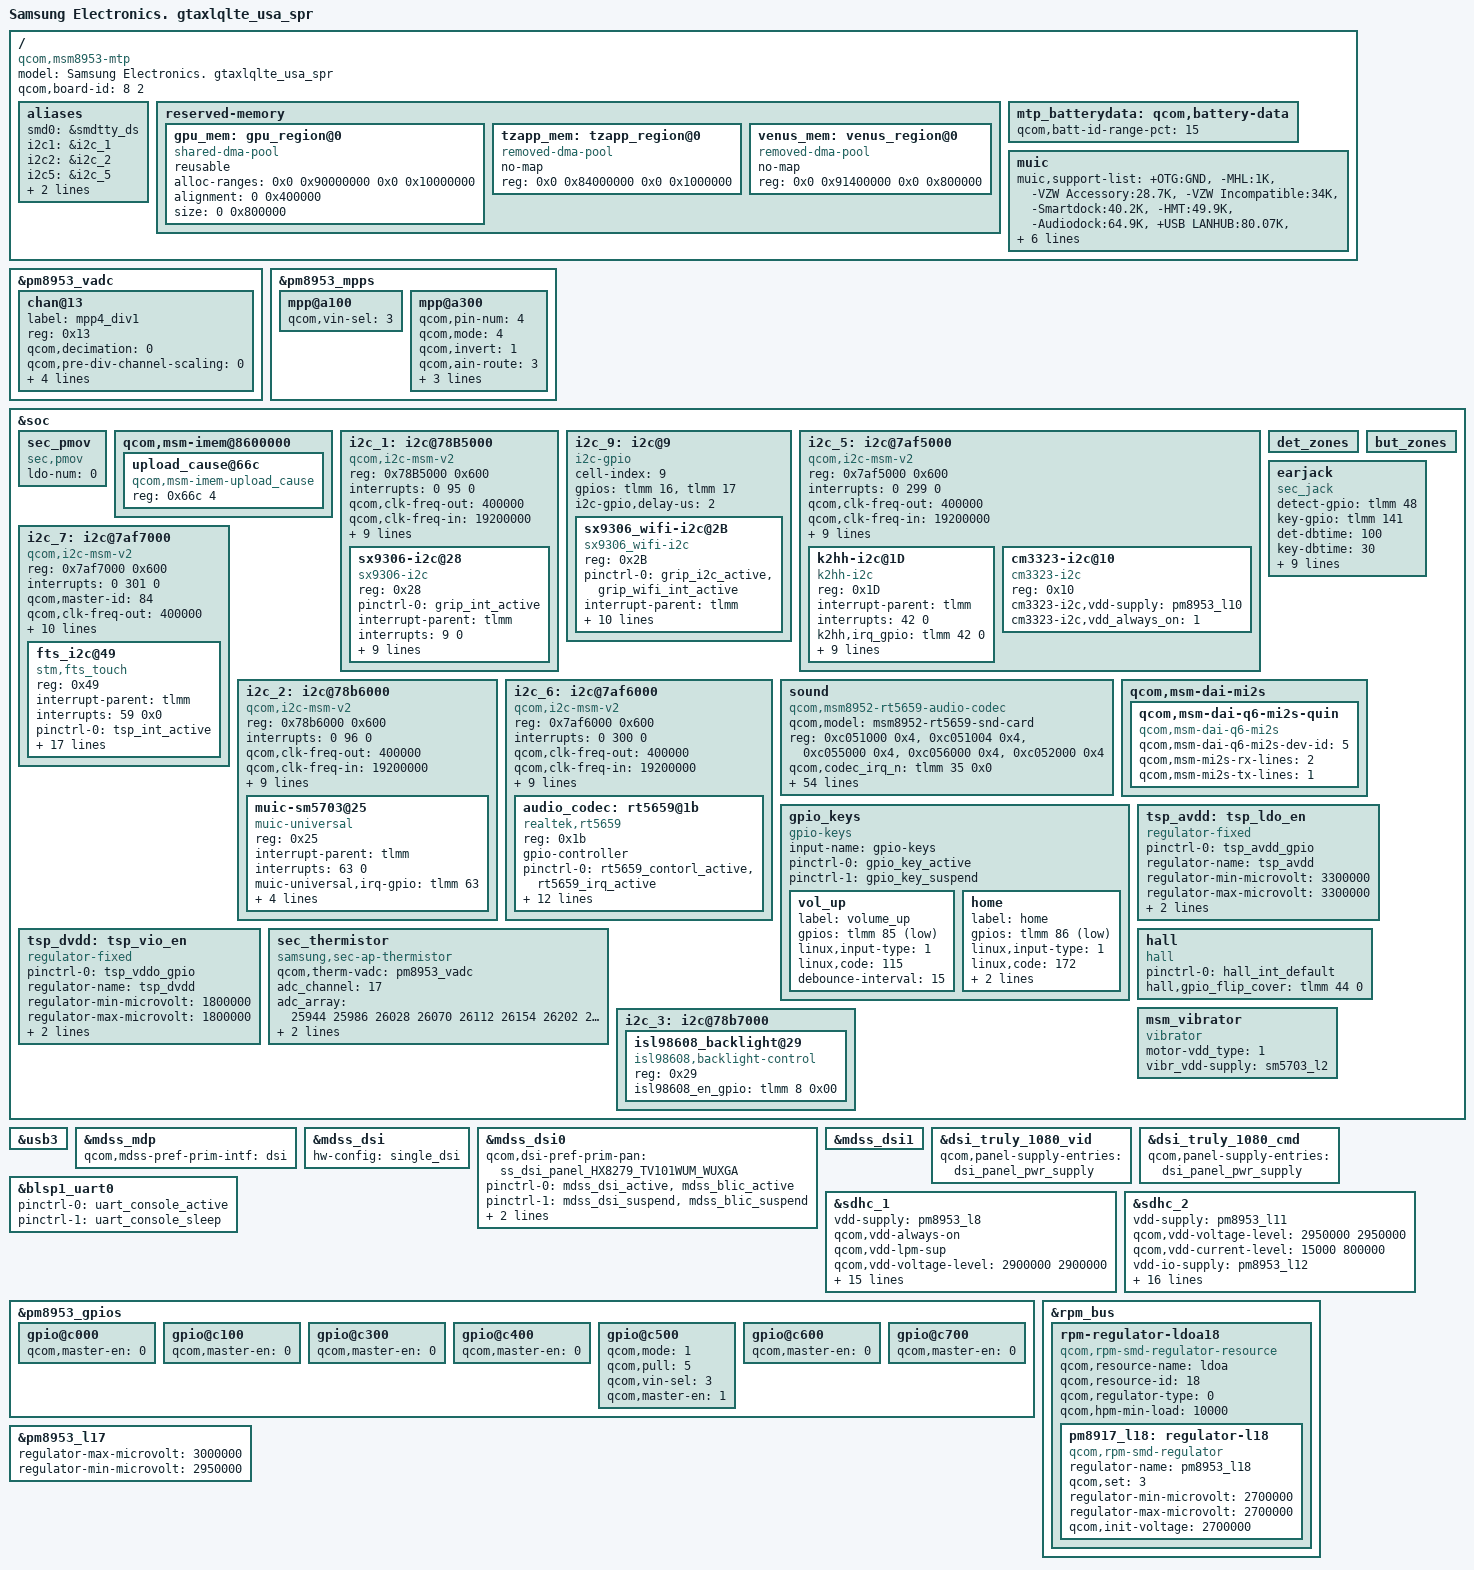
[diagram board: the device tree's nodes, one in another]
/*
 * Copyright (c) 2015, The Linux Foundation. All rights reserved.
 *
 * This program is free software; you can redistribute it and/or modify
 * it under the terms of the GNU General Public License version 2 and
 * only version 2 as published by the Free Software Foundation.
 *
 * This program is distributed in the hope that it will be useful,
 * but WITHOUT ANY WARRANTY; without even the implied warranty of
 * MERCHANTABILITY or FITNESS FOR A PARTICULAR PURPOSE.  See the
 * GNU General Public License for more details.
 */

/dts-v1/;

#include "../../qcom/msm8953.dtsi"
#include "msm-sec-audio.dtsi"
#include "msm8953-sec-common.dtsi"
#include "msm8953-sec-gtaxlqlte_usa_spr-pinctrl-r00.dtsi"
#include "msm8953-sec-gtaxlqlte_usa_spr-battery-r02.dtsi"
#include "msm8953-gtaxlqlte_usa_spr-sm5703.dtsi"
#include "msm8953-camera-sensor-gtaxlq-spr-r00.dtsi"

/ {
	model = "Samsung Electronics. gtaxlqlte_usa_spr";
	compatible = "qcom,msm8953-mtp", "qcom,msm8953", "qcom,mtp";
	qcom,board-id= <8 2>;
	aliases {
		/delete-property/ spi3;

		smd0 = &smdtty_ds;
		i2c1 = &i2c_1;
		i2c2 = &i2c_2;
		i2c5 = &i2c_5;
		i2c6 = &i2c_6;
		i2c7 = &i2c_7;
	};

	reserved-memory {
		/delete-node/ gpu_region@0;
		gpu_mem: gpu_region@0 {
			compatible = "shared-dma-pool";
			reusable;
			alloc-ranges = <0x0 0x90000000 0x0 0x10000000>;
			alignment = <0 0x400000>;
			size = <0 0x800000>;
		};

		/delete-node/ tzapp_region@0;
		tzapp_mem: tzapp_region@0 {
			compatible = "removed-dma-pool";
			no-map;
			reg = <0x0 0x84000000 0x0 0x1000000>;
		};

		/delete-node/ venus_region@0;
		venus_mem: venus_region@0 {
			compatible = "removed-dma-pool";
			no-map;
			reg = <0x0 0x91400000 0x0 0x800000>;
		};
	};
};

&pm8953_vadc {
	chan@13 {
		label = "mpp4_div1";
		reg = <0x13>;
		qcom,decimation = <0>;
		qcom,pre-div-channel-scaling = <0>;
		qcom,calibration-type = "absolute";
		qcom,scale-function = <0>;
		qcom,hw-settle-time = <5>;
		qcom,fast-avg-setup = <0>;
	};
};

&pm8953_mpps {
	mpp@a100 {
		qcom,vin-sel = <3>;
		status = "okay";
	};

	mpp@a300 {
		qcom,pin-num = <4>;
		qcom,mode = <4>; /* AIN input */
		qcom,invert = <1>; /* Enable MPP */
		qcom,ain-route = <3>; /* AMUX 8 */
		qcom,master-en = <1>;
		qcom,src-sel = <0>; /* Function constant */
		qcom,vin-sel = <3>;
		status = "okay";
	};
};

&soc {
	sec_pmov {
		compatible = "sec,pmov";

		/* pinctrl-names = "default";
		pinctrl-0 = <&nc_gpio_default>; */

		ldo-num = <0>;
		/*ldo0-supply = <&pm8953_l17>;
		 ldo1-supply = <&pm8953_lx>; */
	};

	qcom,msm-imem@8600000 {
		upload_cause@66c { /* CONFIG_SEC_DEBUG */
			compatible = "qcom,msm-imem-upload_cause";
			reg = <0x66c 4>;
		};
	};

	i2c_1: i2c@78B5000 { /* BLSP1 QUP0 */
		compatible = "qcom,i2c-msm-v2";
		#address-cells = <1>;
		#size-cells = <0>;
		reg-names = "qup_phys_addr";
		reg = <0x78B5000 0x600>;
		interrupt-names = "qup_irq";
		interrupts = <0 95 0>;
		qcom,clk-freq-out = <400000>;
		qcom,clk-freq-in  = <19200000>;
		clock-names = "iface_clk", "core_clk";
		clocks = <&clock_gcc clk_gcc_blsp1_ahb_clk>,
			<&clock_gcc clk_gcc_blsp1_qup1_i2c_apps_clk>;

		pinctrl-names = "i2c_active", "i2c_sleep";
		pinctrl-0 = <&i2c_1_active>;
		pinctrl-1 = <&i2c_1_sleep>;
		qcom,noise-rjct-scl = <0>;
		qcom,noise-rjct-sda = <0>;
		qcom,master-id = <86>;
		dmas = <&dma_blsp1 4 64 0x20000020 0x20>,
			<&dma_blsp1 5 32 0x20000020 0x20>;
		dma-names = "tx", "rx";

		sx9306-i2c@28{
			compatible = "sx9306-i2c";
			reg = <0x28>;
			pinctrl-names = "default";
			pinctrl-0 = <&grip_int_active>;
			interrupt-parent = <&tlmm>;
			interrupts = <9 0>;
			sx9306-i2c,nirq-gpio = <&tlmm 9 0x00>;
			sx9306-i2c,ctrl0 = <0x14>; /* Scanperiod : 60 */
			sx9306-i2c,ctrl2 = <0x57>; /* Gain: 4, Freq : 167, Resolution : Finest */
			sx9306-i2c,ctrl3 = <0x02>; /* Rawfilter: Medium */
			sx9306-i2c,ctrl5 = <0x0f>; /* AVGNEG:001 AVGPOS : 111 */ 
			sx9306-i2c,normal-thd = <5>; /* normal touch threshold */
			sx9306-i2c,ch-main = <2>; /* channel number */
			sx9306-i2c,ch-sub1 = <0xff>; /*oxff: Not be used sub channel */
			sx9306-i2c,ta-thd = <0x0f>; /* TA threhold : 300 */
		};
	};

	i2c_9: i2c@9 { /* SW I2C */
		cell-index = <9>;
		compatible = "i2c-gpio";
		gpios = <&tlmm 16 0 /* sda */
			&tlmm 17 0 /* scl */
		>;
		i2c-gpio,delay-us = <2>;
		#address-cells = <1>;
		#size-cells = <0>;

		sx9306_wifi-i2c@2B{
			compatible = "sx9306_wifi-i2c";
			reg = <0x2B>;
			pinctrl-names = "default";
			pinctrl-0 = <&grip_i2c_active &grip_wifi_int_active>;
			interrupt-parent = <&tlmm>;
			interrupts = <1 0>;
			sx9306_wifi-i2c,nirq-gpio = <&tlmm 1 0x00>;
			sx9306_wifi-i2c,ctrl0 = <0x04>; /* Scanperiod : 30 */
			sx9306_wifi-i2c,ctrl2 = <0x57>; /* Gain:4, Freq : 167, Resolution : Finest */
			sx9306_wifi-i2c,ctrl3 = <0x02>; /* Rawfilter: Medium */
			sx9306_wifi-i2c,ctrl5 = <0x0f>; /* AVGNEG:001 AVGPOS : 111 */
			sx9306_wifi-i2c,normal-thd = <5>; /* normal touch threshold */
			sx9306_wifi-i2c,ch-main = <2>; /* channel number */
			sx9306_wifi-i2c,ch-sub1 = <0xff>; /*oxff: Not be used sub channel */
			sx9306_wifi-i2c,ta-thd = <0x0f>; /* TA threhold : 300 */	
		};
	};

	i2c_5: i2c@7af5000 { /* BLSP2 QUP1 */
		compatible = "qcom,i2c-msm-v2";
		#address-cells = <1>;
		#size-cells = <0>;
		reg-names = "qup_phys_addr";
		reg = <0x7af5000 0x600>;
		interrupt-names = "qup_irq";
		interrupts = <0 299 0>;
		qcom,clk-freq-out = <400000>;
		qcom,clk-freq-in  = <19200000>;
		clock-names = "iface_clk", "core_clk";
		clocks = <&clock_gcc clk_gcc_blsp2_ahb_clk>,
			<&clock_gcc clk_gcc_blsp2_qup1_i2c_apps_clk>;

		pinctrl-names = "i2c_active", "i2c_sleep";
		pinctrl-0 = <&i2c_5_active>;
		pinctrl-1 = <&i2c_5_sleep>;
		qcom,noise-rjct-scl = <0>;
		qcom,noise-rjct-sda = <0>;
		qcom,master-id = <84>;
		dmas = <&dma_blsp2 4 64 0x20000020 0x20>,
			<&dma_blsp2 5 32 0x20000020 0x20>;
		dma-names = "tx", "rx";

		k2hh-i2c@1D {
			compatible = "k2hh-i2c";
			reg = <0x1D>;
			interrupt-parent = <&tlmm>;
			interrupts = <42 0>;
			k2hh,irq_gpio = <&tlmm 42 0>;
			k2hh,vio-supply = <&pm8953_l5>;
			k2hh,axis_map_x = <0>;
			k2hh,axis_map_y = <1>;
			k2hh,axis_map_z = <2>;
			k2hh,negate_x = <0>;
			k2hh,negate_y = <0>;
			k2hh,negate_z = <1>;
			k2hh,poll_interval = <100>;
			k2hh,min_interval = <2>;
		};

		cm3323-i2c@10 {
			compatible = "cm3323-i2c";
			reg = <0x10>;
			cm3323-i2c,vdd-supply = <&pm8953_l10>;
			cm3323-i2c,vdd_always_on = <1>;
		};
	};

	i2c_7: i2c@7af7000 { /* BLSP2 QUP3 */
		compatible = "qcom,i2c-msm-v2";
		#address-cells = <1>;
		#size-cells = <0>;
		reg-names = "qup_phys_addr";
		reg = <0x7af7000 0x600>;
		interrupt-names = "qup_irq";
		interrupts = <0 301 0>;
		qcom,master-id = <84>;
		qcom,clk-freq-out = <400000>;
		qcom,clk-freq-in  = <19200000>;
		clock-names = "iface_clk", "core_clk";
		clocks = <&clock_gcc clk_gcc_blsp2_ahb_clk>,
			<&clock_gcc clk_gcc_blsp2_qup3_i2c_apps_clk>;
		pinctrl-names = "i2c_active", "i2c_sleep";
		pinctrl-0 = <&i2c_7_active>;
		pinctrl-1 = <&i2c_7_suspend>;
		qcom,noise-rjct-scl = <0>;
		qcom,noise-rjct-sda = <0>;
		qcom,disable-dma;
		dmas = <&dma_blsp2 8 64 0x20000020 0x20>,
			<&dma_blsp2 9 32 0x20000020 0x20>;
		dma-names = "tx", "rx";
	};

	i2c_2: i2c@78b6000 { /* BLSP1 QUP2 */
		compatible = "qcom,i2c-msm-v2";
		#address-cells = <1>;
		#size-cells = <0>;
		reg-names = "qup_phys_addr";
		reg = <0x78b6000 0x600>;
		interrupt-names = "qup_irq";
		interrupts = <0 96 0>;
		qcom,clk-freq-out = <400000>;
		qcom,clk-freq-in  = <19200000>;
		clock-names = "iface_clk", "core_clk";
		clocks = <&clock_gcc clk_gcc_blsp1_ahb_clk>,
			<&clock_gcc clk_gcc_blsp1_qup2_i2c_apps_clk>;
		pinctrl-names = "i2c_active", "i2c_sleep";
		pinctrl-0 = <&i2c_2_active>;
		pinctrl-1 = <&i2c_2_sleep>;
		qcom,noise-rjct-scl = <0>;
		qcom,noise-rjct-sda = <0>;
		qcom,master-id = <86>;
		dmas = <&dma_blsp1 6 64 0x20000020 0x20>,
			<&dma_blsp1 7 32 0x20000020 0x20>;
		dma-names = "tx", "rx";
	};

	i2c_6: i2c@7af6000 { /* BLSP2 QUP2 */
		compatible = "qcom,i2c-msm-v2";
		#address-cells = <1>;
		#size-cells = <0>;
		reg-names = "qup_phys_addr";
		reg = <0x7af6000 0x600>;
		interrupt-names = "qup_irq";
		interrupts = <0 300 0>;
		qcom,clk-freq-out = <400000>;
		qcom,clk-freq-in  = <19200000>;
		clock-names = "iface_clk", "core_clk";
		clocks = <&clock_gcc clk_gcc_blsp2_ahb_clk>,
			<&clock_gcc clk_gcc_blsp2_qup2_i2c_apps_clk>;
		pinctrl-names = "i2c_active", "i2c_sleep";
		pinctrl-0 = <&i2c_6_active>;
		pinctrl-1 = <&i2c_6_sleep>;
		qcom,noise-rjct-scl = <0>;
		qcom,noise-rjct-sda = <0>;
		qcom,master-id = <84>;
		dmas = <&dma_blsp2 6 64 0x20000020 0x20>,
			<&dma_blsp2 7 32 0x20000020 0x20>;
		dma-names = "tx", "rx";

		audio_codec: rt5659@1b {
			compatible = "realtek,rt5659";
			reg = <0x1b>;
			gpio-controller;
			#gpio-cells = <2>;
			pinctrl-names = "default", "sleep";
			pinctrl-0 = <&rt5659_contorl_active &rt5659_irq_active>;
			pinctrl-1 = <&rt5659_contorl_suspend &rt5659_irq_suspend>;

			interrupts = <35 0>;
			interrupt-parent = <&tlmm>;

			realtek,in3-differential;
			realtek,in4-differential;
			realtek,noise-gate1-hp-enabled;

			realtek,gpio_reset = <&tlmm 71 0x0>;
			realtek,gpio_ldo = <&tlmm 74 0x00>;
			realtek,gpio_3p3_en = <&tlmm 73 0x00>;

			imp_table = <
				/* min      max     gain   bias */
				    0       10       10      5
				    11      21       5       5
				    22      85       0       5
				    86      839      0       1
				    840     1023     0       1
			>;
		};
	};

	det_zones: det_zones {
		#list-det-cells = <4>;
	};

	but_zones: but_zones {
		#list-but-cells = <3>;
	};

	earjack {
		compatible = "sec_jack";
		detect-gpio = <&tlmm 48 0x0>;
		key-gpio = <&tlmm 141 0x0>;
		det-dbtime = <100>;
		key-dbtime = <30>;

		det-zones-list = <&det_zones 0 10000 10 2>,
				 <&det_zones 750 10000 10 2>,
				 <&det_zones 751 10000 10 1>,
				 <&det_zones 9999 10000 10 1>;
		but-zones-list = <&but_zones 226 0 235>, /* KEY_MEDIA:226 */
				 <&but_zones 582 236 265>, /* KEY_VOICECOMMAND:582 */
				 <&but_zones 115 266 360>, /* KEY_VOLUMEUP:115 */
				 <&but_zones 114 361 999>; /* KEY_VOLUMEDOWN:114 */

		pinctrl-names = "earjack_gpio_active",
				"earjack_gpio_suspend";
		pinctrl-0 = <&earjack_det_act &earjack_switch_act>;
		pinctrl-1 = <&earjack_det_sus &earjack_switch_sus>;
	};

	sound {
		compatible = "qcom,msm8952-rt5659-audio-codec";
		qcom,model = "msm8952-rt5659-snd-card";
		reg = <0xc051000 0x4>,
		      <0xc051004 0x4>,
		      <0xc055000 0x4>,
		      <0xc056000 0x4>,
		      <0xc052000 0x4>;
		reg-names = "csr_gp_io_mux_mic_ctl",
			    "csr_gp_io_mux_spkr_ctl",
			    "csr_gp_io_lpaif_pri_pcm_pri_mode_muxsel",
			    "csr_gp_io_lpaif_sec_pcm_sec_mode_muxsel",
			    "csr_gp_io_mux_quin_ctl";

		qcom,codec_irq_n = <&tlmm 35 0x0>;

		qcom,mpp-standalone-mode;
		qcom,mpp-channel-scaling = <4 1 1>;
		qcom,earjack-read-vadc = <&pm8953_vadc>;
		qcom,msm-ext-pa = "quinary";
		qcom,msm-mclk-freq = <19200000>;
		qcom,codec_ear_bias = <0>;
		qcom,msm-hs-micbias-type = "External";
		qcom,audio-routing =
			"HP", "HPOL",
			"HP", "HPOR",
			"RCV", "MONOOUT",
			"SPK", "SPOL",
			"SPK", "SPOR",
			"IN1P", "Headset Mic",
			"IN1N", "Headset Mic",
			"IN3P", "MICBIAS3",
			"IN3P", "Sub Mic",
			"IN3N", "Sub Mic",
			"IN4P", "MICBIAS2",
			"IN4P", "Main Mic",
			"IN4N", "Main Mic";
		qcom,msm-gpios =
			"quat_i2s",
			"quin_i2s";
		qcom,pinctrl-names =
			"all_off",
			"quin_i2s_act",
			"quat_i2s_act",
			"quin_quat_i2s_act";
		pinctrl-names =
			"all_off",
			"quin_i2s_act",
			"quat_i2s_act",
			"quin_quat_i2s_act";
		pinctrl-0 = <&quin_tlmm_lines_sus &quin_tlmm_ws_lines_sus &gp_clk1_suspend>;
		pinctrl-1 = <&quin_tlmm_lines_act &quin_tlmm_ws_lines_act &gp_clk1_active>;
		pinctrl-2 = <&quin_tlmm_lines_act &quin_tlmm_ws_lines_act &gp_clk1_active>;
		pinctrl-3 = <&quin_tlmm_lines_act &quin_tlmm_ws_lines_act &gp_clk1_active>;
		asoc-platform = <&pcm0>, <&pcm1>, <&pcm2>, <&voip>, <&voice>,
				<&loopback>, <&compress>, <&hostless>,
				<&afe>, <&lsm>, <&routing>, <&lpa>;
		asoc-platform-names = "msm-pcm-dsp.0", "msm-pcm-dsp.1",
				"msm-pcm-dsp.2", "msm-voip-dsp",
				"msm-pcm-voice", "msm-pcm-loopback",
				"msm-compress-dsp", "msm-pcm-hostless",
				"msm-pcm-afe", "msm-lsm-client",
				"msm-pcm-routing", "msm-pcm-lpa";
		asoc-cpu = <&dai_pri_auxpcm>,
				<&dai_mi2s0>, <&dai_mi2s1>,
				<&dai_mi2s2>, <&dai_mi2s3>,
				<&dai_mi2s5>, <&dai_mi2s6>,
				<&bt_sco_rx>, <&bt_sco_tx>,
				<&int_fm_rx>, <&int_fm_tx>,
				<&afe_pcm_rx>, <&afe_pcm_tx>,
				<&afe_proxy_rx>, <&afe_proxy_tx>,
				<&incall_record_rx>, <&incall_record_tx>,
				<&incall_music_rx>, <&incall_music_2_rx>;
		asoc-cpu-names = "msm-dai-q6-auxpcm.1",
				"msm-dai-q6-mi2s.0", "msm-dai-q6-mi2s.1",
				"msm-dai-q6-mi2s.2", "msm-dai-q6-mi2s.3",
				"msm-dai-q6-mi2s.5", "msm-dai-q6-mi2s.6",
				"msm-dai-q6-dev.12288", "msm-dai-q6-dev.12289",
				"msm-dai-q6-dev.12292", "msm-dai-q6-dev.12293",
				"msm-dai-q6-dev.224", "msm-dai-q6-dev.225",
				"msm-dai-q6-dev.241", "msm-dai-q6-dev.240",
				"msm-dai-q6-dev.32771", "msm-dai-q6-dev.32772",
				"msm-dai-q6-dev.32773", "msm-dai-q6-dev.32770";
		asoc-codec = <&stub_codec>, <&audio_codec>;
		asoc-codec-names = "msm-stub-codec.1", "rt5659";

		clock-names = "ext-mclk";
		clocks = <&clock_gcc clk_gcc_camss_gp1_clk>;
		realtek,hp_impdeance_sensing_enable;
	};

	qcom,msm-dai-mi2s {
		qcom,msm-dai-q6-mi2s-quin {
			compatible = "qcom,msm-dai-q6-mi2s";
			qcom,msm-dai-q6-mi2s-dev-id = <5>;
			qcom,msm-mi2s-rx-lines = <2>;
			qcom,msm-mi2s-tx-lines = <1>;
		};
	};

	gpio_keys {
		compatible = "gpio-keys";
		input-name = "gpio-keys";
		pinctrl-names = "tlmm_gpio_key_active","tlmm_gpio_key_suspend";
		pinctrl-0 = <&gpio_key_active>;
		pinctrl-1 = <&gpio_key_suspend>;

		vol_up {
			label = "volume_up";
			gpios = <&tlmm 85 0x1>;
			linux,input-type = <1>;
			linux,code = <115>;
			debounce-interval = <15>;
		};

		home {
			label = "home";
			gpios = <&tlmm 86 0x1>;
			linux,input-type = <1>;
			linux,code = <172>;
			gpio-key,wakeup;
			debounce-interval = <15>;
		};
	};

	tsp_avdd:tsp_ldo_en {
		compatible = "regulator-fixed";
		pinctrl-names = "default";
		pinctrl-0 = <&tsp_avdd_gpio>;
		regulator-name = "tsp_avdd";
		regulator-min-microvolt = <3300000>;
		regulator-max-microvolt = <3300000>;
		gpio = <&tlmm 95 0>;
		enable-active-high;
	};

	tsp_dvdd:tsp_vio_en {
		compatible = "regulator-fixed";
		pinctrl-names = "default";
		pinctrl-0 = <&tsp_vddo_gpio>;
		regulator-name = "tsp_dvdd";
		regulator-min-microvolt = <1800000>;
		regulator-max-microvolt = <1800000>;
		gpio = <&tlmm 132 0>;
		enable-active-high;
	};

	sec_thermistor {
		compatible = "samsung,sec-ap-thermistor";
		qcom,therm-vadc = <&pm8953_vadc>;
		status = "okay";
		adc_channel = <17>;
		adc_array = <25944 25986 26028 26070 26112 26154 26202 26251
                                         26299 26347 26396 26455 26515 26575 26634 26694
                                         26760 26825 26891 26957 27023 27102 27181 27260
                                         27339 27418 27518 27617 27716 27815 27915 28021
                                         28128 28235 28341 28448 28570 28692 28814 28935
                                         29057 29202 29346 29490 29634 29778 29942 30106
                                         30269 30433 30596 30775 30954 31133 31312 31490
                                         31685 31880 32075 32270 32465 32676 32887 33098
                                         33309 33520 33730 33939 34148 34358 34567 34780
                                         34993 35206 35420 35633 35842 36052 36262 36471
                                         36681 36888 37096 37303 37510 37718 37805 37892
                                         38064 38236 38408 38593 38778 38962 39139 39316
                                         39468 39620 39772 39924 40075 40204 40332 40461
                                         40589 40717 40852 40987 41122 41257 41392>;

		temp_array = <900 890 880 870 860 850 840 830 820 810
			800 790 780 770 760 750 740 730 720 710
			700 690 680 670 660 650 640 630 620 610
			600 590 580 570 560 550 540 530 520 510
			500 490 480 470 460 450 440 430 420 410
			400 390 380 370 360 350 340 330 320 310
			300 290 280 270 260 250 240 230 220 210 
			200 190 180 170 160 150 140 130 120 110 
			100 90 80 70 60 50 40 30 20 10 
			0 (-10) (-20) (-30) (-40) (-50) (-60) (-70) (-80) (-90)
			(-100) (-110) (-120) (-130) (-140) (-150) (-160) (-170) (-180) (-190)
			(-200)>;
	};

	hall {
		compatible = "hall";
		status = "okay";
		pinctrl-names = "default";
		pinctrl-0 = <&hall_int_default>;
		hall,gpio_flip_cover = <&tlmm 44 0>;
	};

	msm_vibrator {
		compatible = "vibrator";
		motor-vdd_type = <1>; /* 0: gpio, 1: pmic */
		vibr_vdd-supply = <&sm5703_l2>;
	};
};

&usb3 {
	/delete-property/ vbus_dwc3-supply;
};

&i2c_7 {
	fts_i2c@49 {
		compatible = "stm,fts_touch";
		reg = <0x49>;
		interrupt-parent = <&tlmm>;
		interrupts = <59 0x0>;
		pinctrl-names = "tsp_gpio_active", "tsp_gpio_suspend";
		pinctrl-0 = <&tsp_int_active>;
		pinctrl-1 = <&tsp_int_suspend>;
		stm,irq_gpio = <&tlmm 59 0x0>;
		stm,irq_type = <8200>;
		stm,tsp_id1 = <&tlmm 67 0x0>;
		stm,tsp_id2 = <&tlmm 68 0x0>;
		stm,project_name = "GTAXLQLTE";
		stm,model_name = "T587P";
		stm,regulator_dvdd = "tsp_dvdd";
		stm,regulator_avdd = "tsp_avdd";
		stm,num_lines = <28 16>;		/* rx tx */
		stm,max_coords = <1199 1919>;	/* x y */
		stm,firmware_name = "tsp_stm/stm_gtaxlqlte.fw";
		stm,num_touchkey = <2>;
		stm,bringup = <0>;
		stm,support_lpm;
		clock-names = "iface_clk", "core_clk";
		clocks = <&clock_gcc clk_gcc_blsp2_ahb_clk>,
			<&clock_gcc clk_gcc_blsp2_qup3_i2c_apps_clk>;
	};
};		

&i2c_2 {
	muic-sm5703@25 {
		compatible = "muic-universal";
		reg = <0x25>;
		interrupt-parent = <&tlmm>;
		interrupts = <63 0>;
		muic-universal,irq-gpio = <&tlmm 63 0x00>;
		sm5705,wakeup;
		muic-universal,chip_name = "sm,sm5703";
		pinctrl-0 = <&sm5703_interrupt_default &sm5703_rst_default>;
	};

};


#include "../../qcom/msm8953-mdss-panels.dtsi"
#include "../../../../../../drivers/video/msm/mdss/samsung/HX8279_TV101WUM/dsi_panel_HX8279_TV101WUM_WUXGA_video.dtsi"
#include "../../../../../../drivers/video/msm/mdss/samsung/PBA_BOOTING_HD/dsi_panel_PBA_BOOTING_hd_video.dtsi"

&mdss_mdp {
	qcom,mdss-pref-prim-intf = "dsi";
};

&mdss_dsi {
	hw-config = "single_dsi";
};

&mdss_dsi0 {
	/delete-property/ lab-supply;
	/delete-property/ ibb-supply;
	qcom,dsi-pref-prim-pan = <&ss_dsi_panel_HX8279_TV101WUM_WUXGA>;
	pinctrl-names = "mdss_default", "mdss_sleep";
	pinctrl-0 = <&mdss_dsi_active &mdss_blic_active>;
	pinctrl-1 = <&mdss_dsi_suspend &mdss_blic_suspend>;

	qcom,platform-reset-gpio = <&tlmm 50 0>;
	qcom,platform-enable-gpio = <&tlmm 94 0>;
};

&mdss_dsi1 {
	/delete-property/ lab-supply;
	/delete-property/ ibb-supply;
};

&soc {
	i2c_3: i2c@78b7000 { /* BLSP1 QUP3 */
		status = "okay";

		isl98608_backlight@29 {
			compatible = "isl98608,backlight-control";
			reg = <0x29>;

			isl98608_en_gpio = <&tlmm 8 0x00>;
		};
	};
};
&dsi_truly_1080_vid {
	qcom,panel-supply-entries = <&dsi_panel_pwr_supply>;
};

&dsi_truly_1080_cmd {
	qcom,panel-supply-entries = <&dsi_panel_pwr_supply>;
};

&blsp1_uart0 {
	status = "ok";
	pinctrl-names = "default";
	pinctrl-0 = <&uart_console_active>;
	pinctrl-1 = <&uart_console_sleep>;
};

&sdhc_1 {
	/* device core power supply */
	vdd-supply = <&pm8953_l8>;
	qcom,vdd-always-on;
	qcom,vdd-lpm-sup;
	qcom,vdd-voltage-level = <2900000 2900000>;
	qcom,vdd-current-level = <200 570000>;

	/* device communication power supply */
	vdd-io-supply = <&pm8953_l5>;
	qcom,vdd-io-always-on;
	qcom,vdd-io-lpm-sup;
	qcom,vdd-io-voltage-level = <1800000 1800000>;
	qcom,vdd-io-current-level = <200 325000>;

	pinctrl-names = "active", "sleep";
	pinctrl-0 = <&sdc1_clk_on &sdc1_cmd_on &sdc1_data_on  &sdc1_rclk_on>;
	pinctrl-1 = <&sdc1_clk_off &sdc1_cmd_off &sdc1_data_off &sdc1_rclk_off>;

	qcom,clk-rates = <400000 20000000 25000000 50000000 100000000 192000000
								384000000>;
	qcom,nonremovable;
	qcom,bus-speed-mode = "HS400_1p8v", "HS200_1p8v", "DDR_1p8v";

	status = "ok";
};

&sdhc_2 {
	/* device core power supply */
	vdd-supply = <&pm8953_l11>;
	qcom,vdd-voltage-level = <2950000 2950000>;
	qcom,vdd-current-level = <15000 800000>;

	/* device communication power supply */
	vdd-io-supply = <&pm8953_l12>;
	qcom,vdd-io-voltage-level = <1800000 2950000>;
	qcom,vdd-io-current-level = <200 22000>;

	pinctrl-names = "active", "sleep";
	pinctrl-0 = <&sdc2_clk_on &sdc2_cmd_on &sdc2_data_on &sdc2_cd_on>;
	pinctrl-1 = <&sdc2_clk_off &sdc2_cmd_off &sdc2_data_off &sdc2_cd_off>;

	#address-cells = <0>;
	interrupt-parent = <&sdhc_2>;
	interrupts = <0 1 2>;
	#interrupt-cells = <1>;
	interrupt-map-mask = <0xffffffff>;
	interrupt-map = <0 &intc 0 125 0
		1 &intc 0 221 0
		2 &tlmm 133 0>;
	interrupt-names = "hc_irq", "pwr_irq", "status_irq";
	cd-gpios = <&tlmm 133 0x1>;

	qcom,clk-rates = <400000 20000000 25000000 50000000 100000000
								177770000>;
	qcom,bus-speed-mode = "SDR12", "SDR25", "SDR50", "DDR50", "SDR104";

	status = "ok";
};

/{
	mtp_batterydata: qcom,battery-data {
		qcom,batt-id-range-pct = <15>;
		#include "../../qcom/batterydata-itech-3000mah.dtsi"
		#include "../../qcom/batterydata-ascent-3450mAh.dtsi"
	};
};

&pm8953_gpios {
	/* GPIO 1*/
	gpio@c000 {
		qcom,master-en = <0>;
		status = "okay";
	};
	/* GPIO 2*/
	gpio@c100 {
		qcom,master-en = <0>;
		status = "okay";
	};
	/* GPIO 4*/
	gpio@c300 {
		qcom,master-en = <0>;
		status = "okay";
	};
	/* GPIO 5*/
	gpio@c400 {
		qcom,master-en = <0>;
		status = "okay";
	};
	/* GPIO 6*/
	gpio@c500 {
		qcom,mode = <1>;
		qcom,pull = <5>;
		qcom,vin-sel = <3>;	/* 1.8V*/
		qcom,master-en = <1>;
		status = "okay";
	};
	/* GPIO 7 */
	gpio@c600 {
		qcom,master-en = <0>;
		status = "okay";
	};
	/* GPIO 8 */
	gpio@c700 {
		qcom,master-en = <0>;
		status = "okay";
	};
};

&rpm_bus {
	rpm-regulator-ldoa18 {
		compatible = "qcom,rpm-smd-regulator-resource";
		qcom,resource-name = "ldoa";
		qcom,resource-id = <18>;
		qcom,regulator-type = <0>;
		qcom,hpm-min-load = <10000>;
		status = "okay";

		pm8917_l18: regulator-l18 {
			compatible = "qcom,rpm-smd-regulator";
			regulator-name = "pm8953_l18";
			qcom,set = <3>;
			regulator-min-microvolt = <2700000>;
			regulator-max-microvolt = <2700000>;
			qcom,init-voltage = <2700000>;
			status = "okay";
		};
	};
};

&pm8953_l17 {
    regulator-max-microvolt = <3000000>;
    regulator-min-microvolt = <2950000>;
};

/ {
	muic {
		status = "okay";
		muic,support-list = "+OTG:GND",
			"-MHL:1K",
			"-VZW Accessory:28.7K",
			"-VZW Incompatible:34K",
			"-Smartdock:40.2K",
			"-HMT:49.9K",
			"-Audiodock:64.9K",
			"+USB LANHUB:80.07K",
			"-Charging Cable:102K",
			"+Game Pad:121K",
			"+Jig USB Off:255K",
			"+Jig USB On:301K",
			"+Deskdock:365K",
			"+TYPE2 Charger:442K",
			"+Jig UART Off:523K",
			"+Jig UART On:619K",
			"+TA:OPEN",
			"+USB:OPEN",
			"+CDP:OPEN",
			"+Undefined Charging:XXX";
	};
};
